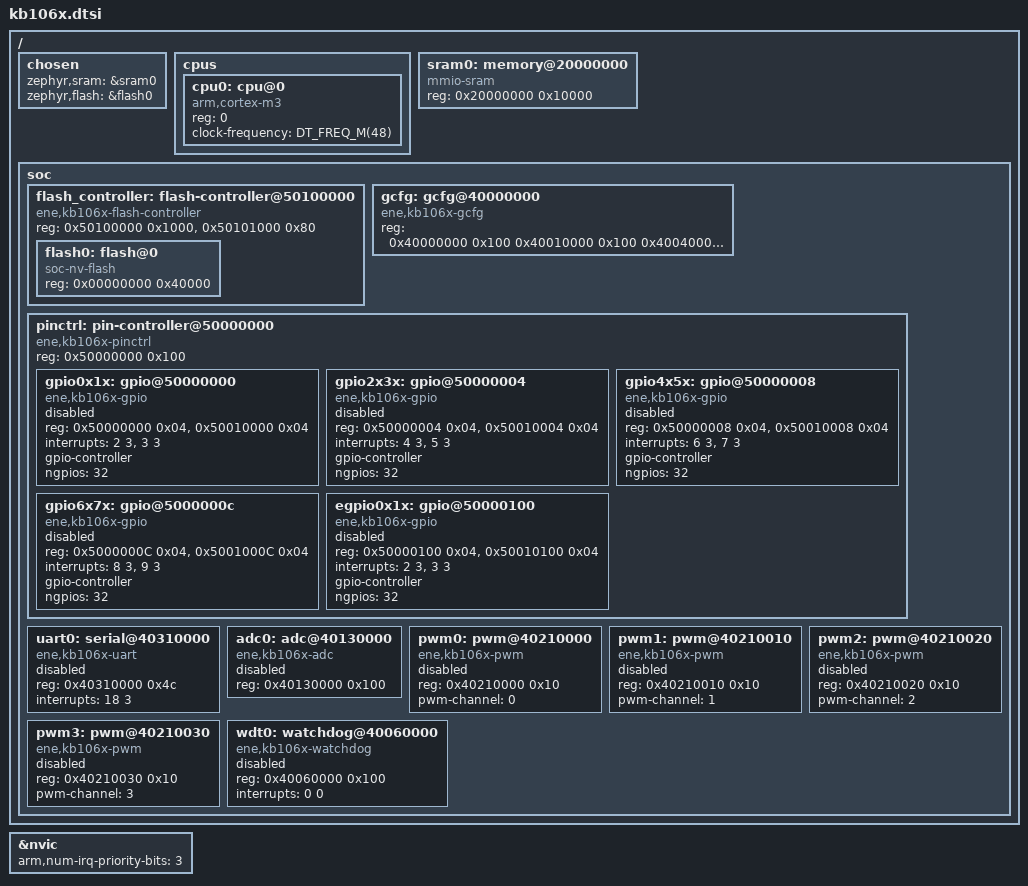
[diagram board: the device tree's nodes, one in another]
/*
 * Copyright (c) 2025 ENE Technology Inc.
 *
 * SPDX-License-Identifier: Apache-2.0
 */

#include <freq.h>
#include <arm/armv7-m.dtsi>

/ {
	chosen {
		zephyr,sram = &sram0;
		zephyr,flash = &flash0;
	};

	cpus {
		#address-cells = <1>;
		#size-cells = <0>;

		cpu0: cpu@0 {
			device_type = "cpu";
			compatible = "arm,cortex-m3";
			reg = <0>;
			clock-frequency = <DT_FREQ_M(48)>;
		};
	};

	sram0: memory@20000000 {
		compatible = "mmio-sram";
		reg = <0x20000000 0x10000>;
	};

	soc: soc {
		flash_controller: flash-controller@50100000 {
			compatible = "ene,kb106x-flash-controller";
			reg = <0x50100000 0x1000>, <0x50101000 0x80>;
			#address-cells = <1>;
			#size-cells = <1>;

			flash0: flash@0 {
				compatible = "soc-nv-flash";
				reg = <0x00000000 0x40000>;
			};
		};

		gcfg: gcfg@40000000 {
			compatible = "ene,kb106x-gcfg";
			/* First reg region is General Configuration registers */
			/* Second reg region is PMU registers */
			/* Third reg region is Vcc0 registers */
			reg = <0x40000000 0x100
			       0x40010000 0x100
			       0x40040000 0x100>;
			reg-names = "gcfg", "pmu", "vcc0";
		};

		pinctrl: pin-controller@50000000 {
			compatible = "ene,kb106x-pinctrl";
			#address-cells = <1>;
			#size-cells = <1>;
			reg = <0x50000000 0x100>;
			status = "okay";

			gpio0x1x: gpio@50000000 {
				compatible = "ene,kb106x-gpio";
				reg = <0x50000000 0x04>, <0x50010000 0x04>;
				interrupts = <2 3>, <3 3>;
				gpio-controller;
				#gpio-cells = <2>;
				ngpios = <32>;
				status = "disabled";
			};

			gpio2x3x: gpio@50000004 {
				compatible = "ene,kb106x-gpio";
				reg = <0x50000004 0x04>, <0x50010004 0x04>;
				interrupts = <4 3>, <5 3>;
				gpio-controller;
				#gpio-cells = <2>;
				ngpios = <32>;
				status = "disabled";
			};

			gpio4x5x: gpio@50000008 {
				compatible = "ene,kb106x-gpio";
				reg = <0x50000008 0x04>, <0x50010008 0x04>;
				interrupts = <6 3>, <7 3>;
				gpio-controller;
				#gpio-cells = <2>;
				ngpios = <32>;
				status = "disabled";
			};

			gpio6x7x: gpio@5000000c {
				compatible = "ene,kb106x-gpio";
				reg = <0x5000000C 0x04>, <0x5001000C 0x04>;
				interrupts = <8 3>, <9 3>;
				gpio-controller;
				#gpio-cells = <2>;
				ngpios = <32>;
				status = "disabled";
			};

			egpio0x1x: gpio@50000100 {
				compatible = "ene,kb106x-gpio";
				reg = <0x50000100 0x04>, <0x50010100 0x04>;
				interrupts = <2 3>, <3 3>;
				gpio-controller;
				#gpio-cells = <2>;
				ngpios = <32>;
				status = "disabled";
			};
		};

		uart0: serial@40310000 {
			compatible = "ene,kb106x-uart";
			reg = <0x40310000 0x4c>;
			interrupts = <18 3>;
			status = "disabled";
		};

		adc0: adc@40130000 {
			compatible = "ene,kb106x-adc";
			reg = <0x40130000 0x100>;
			status = "disabled";
			#io-channel-cells = <1>;
		};

		pwm0: pwm@40210000 {
			compatible = "ene,kb106x-pwm";
			reg = <0x40210000 0x10>;
			pwm-channel = <0>;
			#pwm-cells = <3>;
			status = "disabled";
		};

		pwm1: pwm@40210010 {
			compatible = "ene,kb106x-pwm";
			reg = <0x40210010 0x10>;
			pwm-channel = <1>;
			#pwm-cells = <3>;
			status = "disabled";
		};

		pwm2: pwm@40210020 {
			compatible = "ene,kb106x-pwm";
			reg = <0x40210020 0x10>;
			pwm-channel = <2>;
			#pwm-cells = <3>;
			status = "disabled";
		};

		pwm3: pwm@40210030 {
			compatible = "ene,kb106x-pwm";
			reg = <0x40210030 0x10>;
			pwm-channel = <3>;
			#pwm-cells = <3>;
			status = "disabled";
		};

		wdt0: watchdog@40060000 {
			compatible = "ene,kb106x-watchdog";
			reg = <0x40060000 0x100>;
			interrupts = <0 0>;
			status = "disabled";
		};
	};
};

&nvic {
	arm,num-irq-priority-bits = <3>;
};
